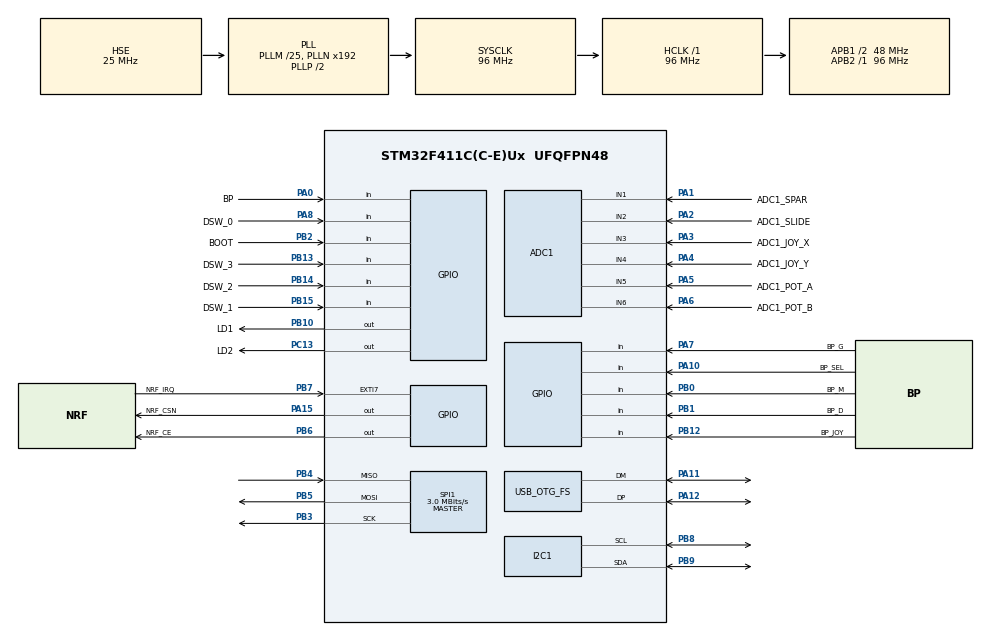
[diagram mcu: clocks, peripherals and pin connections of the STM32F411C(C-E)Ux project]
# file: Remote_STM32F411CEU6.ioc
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ADC1.Channel-0\#ChannelRegularConversion=ADC_CHANNEL_1
ADC1.Channel-1\#ChannelRegularConversion=ADC_CHANNEL_2
ADC1.Channel-2\#ChannelRegularConversion=ADC_CHANNEL_3
ADC1.Channel-3\#ChannelRegularConversion=ADC_CHANNEL_4
ADC1.Channel-4\#ChannelRegularConversion=ADC_CHANNEL_5
ADC1.Channel-5\#ChannelRegularConversion=ADC_CHANNEL_6
ADC1.ContinuousConvMode=ENABLE
ADC1.DMAContinuousRequests=ENABLE
ADC1.DataAlign=ADC_DATAALIGN_RIGHT
ADC1.NbrOfConversion=6
ADC1.NbrOfConversionFlag=1
ADC1.Rank-0\#ChannelRegularConversion=1
ADC1.Rank-1\#ChannelRegularConversion=2
ADC1.Rank-2\#ChannelRegularConversion=3
ADC1.Rank-3\#ChannelRegularConversion=4
ADC1.Rank-4\#ChannelRegularConversion=5
ADC1.Rank-5\#ChannelRegularConversion=6
ADC1.SamplingTime-0\#ChannelRegularConversion=ADC_SAMPLETIME_480CYCLES
ADC1.SamplingTime-1\#ChannelRegularConversion=ADC_SAMPLETIME_480CYCLES
ADC1.SamplingTime-2\#ChannelRegularConversion=ADC_SAMPLETIME_480CYCLES
ADC1.SamplingTime-3\#ChannelRegularConversion=ADC_SAMPLETIME_480CYCLES
ADC1.SamplingTime-4\#ChannelRegularConversion=ADC_SAMPLETIME_480CYCLES
ADC1.SamplingTime-5\#ChannelRegularConversion=ADC_SAMPLETIME_480CYCLES
ADC1.master=1
Dma.ADC1.0.Direction=DMA_PERIPH_TO_MEMORY
Dma.ADC1.0.FIFOMode=DMA_FIFOMODE_DISABLE
Dma.ADC1.0.Instance=DMA2_Stream0
Dma.ADC1.0.MemDataAlignment=DMA_MDATAALIGN_WORD
Dma.ADC1.0.MemInc=DMA_MINC_ENABLE
Dma.ADC1.0.Mode=DMA_CIRCULAR
Dma.ADC1.0.PeriphDataAlignment=DMA_PDATAALIGN_WORD
Dma.ADC1.0.PeriphInc=DMA_PINC_DISABLE
Dma.ADC1.0.Priority=DMA_PRIORITY_HIGH
Dma.Request0=ADC1
FREERTOS.Tasks01=defaultTask,24,128,StartDefaultTask,Default,NULL,Dynamic,NULL,NULL;send_usb_data,24,128,send_usb_data_func,Default,NULL,Dynamic,NULL,NULL;read_nrf,25,128,read_nrf_func,Default,NULL,Dynamic,NULL,NULL;send_nrf,26,128,send_nrf_func,Default,NULL,Dynamic,NULL,NULL
FREERTOS.configUSE_NEWLIB_REENTRANT=1
Mcu.Family=STM32F4
Mcu.Name=STM32F411C(C-E)Ux
Mcu.Package=UFQFPN48
NVIC.ADC_IRQn=true\:5\:0\:true\:false\:true\:true\:true\:true\:true
NVIC.DMA2_Stream0_IRQn=true\:5\:0\:false\:false\:true\:true\:false\:true\:true
NVIC.OTG_FS_IRQn=true\:5\:0\:false\:false\:true\:true\:false\:true\:true
NVIC.PriorityGroup=NVIC_PRIORITYGROUP_4
NVIC.TIM2_IRQn=true\:15\:0\:false\:false\:true\:false\:false\:true\:true
NVIC.TimeBase=TIM2_IRQn
NVIC.TimeBaseIP=TIM2
PA0-WKUP.GPIO_Label=BP
PA0-WKUP.GPIO_PuPd=GPIO_PULLUP
PA0-WKUP.Signal=GPIO_Input
PA1.GPIO_Label=ADC1_SPAR
PA1.Signal=ADCx_IN1
PA10.GPIO_Label=BP_SEL
PA10.GPIO_PuPd=GPIO_PULLUP
PA10.Signal=GPIO_Input
PA11.Mode=Device_Only
PA11.Signal=USB_OTG_FS_DM
PA12.Mode=Device_Only
PA12.Signal=USB_OTG_FS_DP
PA13.Mode=Serial_Wire
PA13.Signal=SYS_JTMS-SWDIO
PA14.Mode=Serial_Wire
PA14.Signal=SYS_JTCK-SWCLK
PA15.GPIO_Label=NRF_CSN
PA15.Signal=GPIO_Output
PA2.GPIO_Label=ADC1_SLIDE
PA2.Signal=ADCx_IN2
PA3.GPIO_Label=ADC1_JOY_X
PA3.Signal=ADCx_IN3
PA4.GPIO_Label=ADC1_JOY_Y
PA4.Signal=ADCx_IN4
PA5.GPIO_Label=ADC1_POT_A
PA5.Signal=ADCx_IN5
PA6.GPIO_Label=ADC1_POT_B
PA6.Signal=ADCx_IN6
PA7.GPIO_Label=BP_G
PA7.GPIO_PuPd=GPIO_PULLUP
PA7.Signal=GPIO_Input
PA8.GPIO_Label=DSW_0
PA8.GPIO_PuPd=GPIO_PULLUP
PA8.Signal=GPIO_Input
PB0.GPIO_Label=BP_M
PB0.GPIO_PuPd=GPIO_PULLUP
PB0.Signal=GPIO_Input
PB1.GPIO_Label=BP_D
PB1.GPIO_PuPd=GPIO_PULLUP
PB1.Signal=GPIO_Input
PB10.GPIO_Label=LD1
PB10.Signal=GPIO_Output
PB12.GPIO_Label=BP_JOY
PB12.GPIO_PuPd=GPIO_PULLUP
PB12.Signal=GPIO_Input
PB13.GPIO_Label=DSW_3
PB13.GPIO_PuPd=GPIO_PULLUP
PB13.Signal=GPIO_Input
PB14.GPIO_Label=DSW_2
PB14.GPIO_PuPd=GPIO_PULLUP
PB14.Signal=GPIO_Input
PB15.GPIO_Label=DSW_1
PB15.GPIO_PuPd=GPIO_PULLUP
PB15.Signal=GPIO_Input
PB2.GPIO_Label=BOOT
PB2.GPIO_PuPd=GPIO_NOPULL
PB2.Signal=GPIO_Input
PB3.Mode=Full_Duplex_Master
PB3.Signal=SPI1_SCK
PB4.Mode=Full_Duplex_Master
PB4.Signal=SPI1_MISO
PB5.Mode=Full_Duplex_Master
PB5.Signal=SPI1_MOSI
PB6.GPIO_Label=NRF_CE
PB6.Signal=GPIO_Output
PB7.GPIO_Label=NRF_IRQ
PB7.Signal=GPXTI7
PB8.Mode=I2C
PB8.Signal=I2C1_SCL
PB9.Mode=I2C
PB9.Signal=I2C1_SDA
PC13-ANTI_TAMP.GPIO_Label=LD2
PC13-ANTI_TAMP.GPIO_ModeDefaultOutputPP=GPIO_MODE_OUTPUT_OD
PC13-ANTI_TAMP.GPIO_PuPd=GPIO_NOPULL
PC13-ANTI_TAMP.Signal=GPIO_Output
PC14-OSC32_IN.Mode=LSE-External-Oscillator
PC14-OSC32_IN.Signal=RCC_OSC32_IN
PC15-OSC32_OUT.Mode=LSE-External-Oscillator
PC15-OSC32_OUT.Signal=RCC_OSC32_OUT
PH0\ -\ OSC_IN.Mode=HSE-External-Oscillator
PH0\ -\ OSC_IN.Signal=RCC_OSC_IN
PH1\ -\ OSC_OUT.Mode=HSE-External-Oscillator
PH1\ -\ OSC_OUT.Signal=RCC_OSC_OUT
ProjectManager.HeapSize=0x200
ProjectManager.StackSize=0x400
ProjectManager.TargetToolchain=STM32CubeIDE
RCC.48MHZClocksFreq_Value=48000000
RCC.AHBFreq_Value=96000000
RCC.APB1CLKDivider=RCC_HCLK_DIV2
RCC.APB1Freq_Value=48000000
RCC.APB1TimFreq_Value=96000000
RCC.APB2Freq_Value=96000000
RCC.APB2TimFreq_Value=96000000
RCC.CortexFreq_Value=96000000
RCC.HCLKFreq_Value=96000000
RCC.HSE_Timout=100
RCC.HSE_VALUE=25000000
RCC.HSI_VALUE=16000000
RCC.PLLM=25
RCC.SYSCLKFreq_VALUE=96000000
RCC.SYSCLKSource=RCC_SYSCLKSOURCE_PLLCLK
RCC.VCOOutputFreq_Value=192000000
SH.ADCx_IN1.0=ADC1_IN1,IN1
SH.ADCx_IN2.0=ADC1_IN2,IN2
SH.ADCx_IN3.0=ADC1_IN3,IN3
SH.ADCx_IN4.0=ADC1_IN4,IN4
SH.ADCx_IN5.0=ADC1_IN5,IN5
SH.ADCx_IN6.0=ADC1_IN6,IN6
SPI1.BaudRatePrescaler=SPI_BAUDRATEPRESCALER_32
SPI1.CalculateBaudRate=3.0 MBits/s
SPI1.Direction=SPI_DIRECTION_2LINES
SPI1.Mode=SPI_MODE_MASTER
SPI1.VirtualType=VM_MASTER
USB_DEVICE.CLASS_NAME_FS=CDC
USB_DEVICE.VirtualMode=Cdc
USB_DEVICE.VirtualModeFS=Cdc_FS
USB_OTG_FS.VirtualMode=Device_Only
VP_FREERTOS_VS_CMSIS_V2.Mode=CMSIS_V2
VP_SYS_VS_tim2.Mode=TIM2
VP_USB_DEVICE_VS_USB_DEVICE_CDC_FS.Mode=CDC_FS
board=custom

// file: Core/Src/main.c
/* USER CODE BEGIN Header */
/**
  ******************************************************************************
  * @file           : main.c
  * @brief          : Main program body
  ******************************************************************************
  * @attention
  *
  * Copyright (c) 2025 STMicroelectronics.
  * All rights reserved.
  *
  * This software is licensed under terms that can be found in the LICENSE file
  * in the root directory of this software component.
  * If no LICENSE file comes with this software, it is provided AS-IS.
  *
  ******************************************************************************
  */
/* USER CODE END Header */
#include "main.h"
#include "cmsis_os.h"
#include "usb_device.h"

/* USER CODE BEGIN Includes */
#include "usbd_cdc_if.h"
#include "radio.h"
/* USER CODE END Includes */

ADC_HandleTypeDef hadc1;
DMA_HandleTypeDef hdma_adc1;

I2C_HandleTypeDef hi2c1;

SPI_HandleTypeDef hspi1;

/* Definitions for defaultTask */
osThreadId_t defaultTaskHandle;
const osThreadAttr_t defaultTask_attributes = {
  .name = "defaultTask",
  .stack_size = 128 * 4,
  .priority = (osPriority_t) osPriorityNormal,
};
/* Definitions for send_usb_data */
osThreadId_t send_usb_dataHandle;
const osThreadAttr_t send_usb_data_attributes = {
  .name = "send_usb_data",
  .stack_size = 128 * 4,
  .priority = (osPriority_t) osPriorityNormal,
};
/* Definitions for read_nrf */
osThreadId_t read_nrfHandle;
const osThreadAttr_t read_nrf_attributes = {
  .name = "read_nrf",
  .stack_size = 128 * 4,
  .priority = (osPriority_t) osPriorityNormal1,
};
/* Definitions for send_nrf */
osThreadId_t send_nrfHandle;
const osThreadAttr_t send_nrf_attributes = {
  .name = "send_nrf",
  .stack_size = 128 * 4,
  .priority = (osPriority_t) osPriorityNormal2,
};
/* USER CODE BEGIN PV */
uint16_t pot1;
uint16_t pot2;
uint16_t pot3;
uint16_t pot4;
uint16_t pot5;
uint16_t pot6;
uint32_t readvalue[6];
/* USER CODE END PV */

void SystemClock_Config(void);
static void MX_GPIO_Init(void);
static void MX_DMA_Init(void);
static void MX_SPI1_Init(void);
static void MX_I2C1_Init(void);
static void MX_ADC1_Init(void);
void StartDefaultTask(void *argument);
void send_usb_data_func(void *argument);
void read_nrf_func(void *argument);
void send_nrf_func(void *argument);

int main(void)
{

  /* MCU Configuration--------------------------------------------------------*/

  /* Reset of all peripherals, Initializes the Flash interface and the Systick. */
  HAL_Init();

  /* Configure the system clock */
  SystemClock_Config();

  /* Initialize all configured peripherals */
  MX_GPIO_Init();
  MX_DMA_Init();
  MX_SPI1_Init();
  MX_I2C1_Init();
  MX_ADC1_Init();

  /* Init scheduler */
  osKernelInitialize();

  /* Create the thread(s) */
  /* creation of defaultTask */
  defaultTaskHandle = osThreadNew(StartDefaultTask, NULL, &defaultTask_attributes);

  /* creation of send_usb_data */
  send_usb_dataHandle = osThreadNew(send_usb_data_func, NULL, &send_usb_data_attributes);

  /* creation of read_nrf */
  read_nrfHandle = osThreadNew(read_nrf_func, NULL, &read_nrf_attributes);

  /* creation of send_nrf */
  send_nrfHandle = osThreadNew(send_nrf_func, NULL, &send_nrf_attributes);

  /* Start scheduler */
  osKernelStart();

  /* We should never get here as control is now taken by the scheduler */

  /* Infinite loop */
  while (1)
  {

  }
}

void SystemClock_Config(void)
{
  RCC_OscInitTypeDef RCC_OscInitStruct = {0};
  RCC_ClkInitTypeDef RCC_ClkInitStruct = {0};

  /** Configure the main internal regulator output voltage
  */
  __HAL_RCC_PWR_CLK_ENABLE();
  __HAL_PWR_VOLTAGESCALING_CONFIG(PWR_REGULATOR_VOLTAGE_SCALE1);

  /** Initializes the RCC Oscillators according to the specified parameters
  * in the RCC_OscInitTypeDef structure.
  */
  RCC_OscInitStruct.OscillatorType = RCC_OSCILLATORTYPE_HSE;
  RCC_OscInitStruct.HSEState = RCC_HSE_ON;
  RCC_OscInitStruct.PLL.PLLState = RCC_PLL_ON;
  RCC_OscInitStruct.PLL.PLLSource = RCC_PLLSOURCE_HSE;
  RCC_OscInitStruct.PLL.PLLM = 25;
  RCC_OscInitStruct.PLL.PLLN = 192;
  RCC_OscInitStruct.PLL.PLLP = RCC_PLLP_DIV2;
  RCC_OscInitStruct.PLL.PLLQ = 4;
  if (HAL_RCC_OscConfig(&RCC_OscInitStruct) != HAL_OK)
  {
    Error_Handler();
  }

  /** Initializes the CPU, AHB and APB buses clocks
  */
  RCC_ClkInitStruct.ClockType = RCC_CLOCKTYPE_HCLK|RCC_CLOCKTYPE_SYSCLK
                              |RCC_CLOCKTYPE_PCLK1|RCC_CLOCKTYPE_PCLK2;
  RCC_ClkInitStruct.SYSCLKSource = RCC_SYSCLKSOURCE_PLLCLK;
  RCC_ClkInitStruct.AHBCLKDivider = RCC_SYSCLK_DIV1;
  RCC_ClkInitStruct.APB1CLKDivider = RCC_HCLK_DIV2;
  RCC_ClkInitStruct.APB2CLKDivider = RCC_HCLK_DIV1;

  if (HAL_RCC_ClockConfig(&RCC_ClkInitStruct, FLASH_LATENCY_3) != HAL_OK)
  {
    Error_Handler();
  }
}

static void MX_ADC1_Init(void)
{

  ADC_ChannelConfTypeDef sConfig = {0};

  /** Configure the global features of the ADC (Clock, Resolution, Data Alignment and number of conversion)
  */
  hadc1.Instance = ADC1;
  hadc1.Init.ClockPrescaler = ADC_CLOCK_SYNC_PCLK_DIV4;
  hadc1.Init.Resolution = ADC_RESOLUTION_12B;
  hadc1.Init.ScanConvMode = ENABLE;
  hadc1.Init.ContinuousConvMode = ENABLE;
  hadc1.Init.DiscontinuousConvMode = DISABLE;
  hadc1.Init.ExternalTrigConvEdge = ADC_EXTERNALTRIGCONVEDGE_NONE;
  hadc1.Init.ExternalTrigConv = ADC_SOFTWARE_START;
  hadc1.Init.DataAlign = ADC_DATAALIGN_RIGHT;
  hadc1.Init.NbrOfConversion = 6;
  hadc1.Init.DMAContinuousRequests = ENABLE;
  hadc1.Init.EOCSelection = ADC_EOC_SINGLE_CONV;
  if (HAL_ADC_Init(&hadc1) != HAL_OK)
  {
    Error_Handler();
  }

  /** Configure for the selected ADC regular channel its corresponding rank in the sequencer and its sample time.
  */
  sConfig.Channel = ADC_CHANNEL_1;
  sConfig.Rank = 1;
  sConfig.SamplingTime = ADC_SAMPLETIME_480CYCLES;
  if (HAL_ADC_ConfigChannel(&hadc1, &sConfig) != HAL_OK)
  {
    Error_Handler();
  }

  /** Configure for the selected ADC regular channel its corresponding rank in the sequencer and its sample time.
  */
  sConfig.Channel = ADC_CHANNEL_2;
  sConfig.Rank = 2;
  if (HAL_ADC_ConfigChannel(&hadc1, &sConfig) != HAL_OK)
  {
    Error_Handler();
  }

  /** Configure for the selected ADC regular channel its corresponding rank in the sequencer and its sample time.
  */
  sConfig.Channel = ADC_CHANNEL_3;
  sConfig.Rank = 3;
  if (HAL_ADC_ConfigChannel(&hadc1, &sConfig) != HAL_OK)
  {
    Error_Handler();
  }

  /** Configure for the selected ADC regular channel its corresponding rank in the sequencer and its sample time.
  */
  sConfig.Channel = ADC_CHANNEL_4;
  sConfig.Rank = 4;
  if (HAL_ADC_ConfigChannel(&hadc1, &sConfig) != HAL_OK)
  {
    Error_Handler();
  }

  /** Configure for the selected ADC regular channel its corresponding rank in the sequencer and its sample time.
  */
  sConfig.Channel = ADC_CHANNEL_5;
  sConfig.Rank = 5;
  if (HAL_ADC_ConfigChannel(&hadc1, &sConfig) != HAL_OK)
  {
    Error_Handler();
  }

  /** Configure for the selected ADC regular channel its corresponding rank in the sequencer and its sample time.
  */
  sConfig.Channel = ADC_CHANNEL_6;
  sConfig.Rank = 6;
  if (HAL_ADC_ConfigChannel(&hadc1, &sConfig) != HAL_OK)
  {
    Error_Handler();
  }

}

static void MX_I2C1_Init(void)
{

  hi2c1.Instance = I2C1;
  hi2c1.Init.ClockSpeed = 100000;
  hi2c1.Init.DutyCycle = I2C_DUTYCYCLE_2;
  hi2c1.Init.OwnAddress1 = 0;
  hi2c1.Init.AddressingMode = I2C_ADDRESSINGMODE_7BIT;
  hi2c1.Init.DualAddressMode = I2C_DUALADDRESS_DISABLE;
  hi2c1.Init.OwnAddress2 = 0;
  hi2c1.Init.GeneralCallMode = I2C_GENERALCALL_DISABLE;
  hi2c1.Init.NoStretchMode = I2C_NOSTRETCH_DISABLE;
  if (HAL_I2C_Init(&hi2c1) != HAL_OK)
  {
    Error_Handler();
  }

}

static void MX_SPI1_Init(void)
{

  /* SPI1 parameter configuration*/
  hspi1.Instance = SPI1;
  hspi1.Init.Mode = SPI_MODE_MASTER;
  hspi1.Init.Direction = SPI_DIRECTION_2LINES;
  hspi1.Init.DataSize = SPI_DATASIZE_8BIT;
  hspi1.Init.CLKPolarity = SPI_POLARITY_LOW;
  hspi1.Init.CLKPhase = SPI_PHASE_1EDGE;
  hspi1.Init.NSS = SPI_NSS_SOFT;
  hspi1.Init.BaudRatePrescaler = SPI_BAUDRATEPRESCALER_32;
  hspi1.Init.FirstBit = SPI_FIRSTBIT_MSB;
  hspi1.Init.TIMode = SPI_TIMODE_DISABLE;
  hspi1.Init.CRCCalculation = SPI_CRCCALCULATION_DISABLE;
  hspi1.Init.CRCPolynomial = 10;
  if (HAL_SPI_Init(&hspi1) != HAL_OK)
  {
    Error_Handler();
  }

}

static void MX_DMA_Init(void)
{

  /* DMA controller clock enable */
  __HAL_RCC_DMA2_CLK_ENABLE();

  /* DMA interrupt init */
  /* DMA2_Stream0_IRQn interrupt configuration */
  HAL_NVIC_SetPriority(DMA2_Stream0_IRQn, 5, 0);
  HAL_NVIC_EnableIRQ(DMA2_Stream0_IRQn);

}

static void MX_GPIO_Init(void)
{
  GPIO_InitTypeDef GPIO_InitStruct = {0};

  /* GPIO Ports Clock Enable */
  __HAL_RCC_GPIOC_CLK_ENABLE();
  __HAL_RCC_GPIOH_CLK_ENABLE();
  __HAL_RCC_GPIOA_CLK_ENABLE();
  __HAL_RCC_GPIOB_CLK_ENABLE();

  /*Configure GPIO pin Output Level */
  HAL_GPIO_WritePin(LD2_GPIO_Port, LD2_Pin, GPIO_PIN_RESET);

  /*Configure GPIO pin Output Level */
  HAL_GPIO_WritePin(GPIOB, LD1_Pin|NRF_CE_Pin, GPIO_PIN_RESET);

  /*Configure GPIO pin Output Level */
  HAL_GPIO_WritePin(NRF_CSN_GPIO_Port, NRF_CSN_Pin, GPIO_PIN_RESET);

  /*Configure GPIO pin : LD2_Pin */
  GPIO_InitStruct.Pin = LD2_Pin;
  GPIO_InitStruct.Mode = GPIO_MODE_OUTPUT_OD;
  GPIO_InitStruct.Pull = GPIO_NOPULL;
  GPIO_InitStruct.Speed = GPIO_SPEED_FREQ_LOW;
  HAL_GPIO_Init(LD2_GPIO_Port, &GPIO_InitStruct);

  /*Configure GPIO pins : BP_Pin BP_G_Pin DSW_0_Pin BP_SEL_Pin */
  GPIO_InitStruct.Pin = BP_Pin|BP_G_Pin|DSW_0_Pin|BP_SEL_Pin;
  GPIO_InitStruct.Mode = GPIO_MODE_INPUT;
  GPIO_InitStruct.Pull = GPIO_PULLUP;
  HAL_GPIO_Init(GPIOA, &GPIO_InitStruct);

  /*Configure GPIO pins : BP_M_Pin BP_D_Pin BP_JOY_Pin DSW_3_Pin
                           DSW_2_Pin DSW_1_Pin */
  GPIO_InitStruct.Pin = BP_M_Pin|BP_D_Pin|BP_JOY_Pin|DSW_3_Pin
                          |DSW_2_Pin|DSW_1_Pin;
  GPIO_InitStruct.Mode = GPIO_MODE_INPUT;
  GPIO_InitStruct.Pull = GPIO_PULLUP;
  HAL_GPIO_Init(GPIOB, &GPIO_InitStruct);

  /*Configure GPIO pin : BOOT_Pin */
  GPIO_InitStruct.Pin = BOOT_Pin;
  GPIO_InitStruct.Mode = GPIO_MODE_INPUT;
  GPIO_InitStruct.Pull = GPIO_NOPULL;
  HAL_GPIO_Init(BOOT_GPIO_Port, &GPIO_InitStruct);

  /*Configure GPIO pins : LD1_Pin NRF_CE_Pin */
  GPIO_InitStruct.Pin = LD1_Pin|NRF_CE_Pin;
  GPIO_InitStruct.Mode = GPIO_MODE_OUTPUT_PP;
  GPIO_InitStruct.Pull = GPIO_NOPULL;
  GPIO_InitStruct.Speed = GPIO_SPEED_FREQ_LOW;
  HAL_GPIO_Init(GPIOB, &GPIO_InitStruct);

  /*Configure GPIO pin : NRF_CSN_Pin */
  GPIO_InitStruct.Pin = NRF_CSN_Pin;
  GPIO_InitStruct.Mode = GPIO_MODE_OUTPUT_PP;
  GPIO_InitStruct.Pull = GPIO_NOPULL;
  GPIO_InitStruct.Speed = GPIO_SPEED_FREQ_LOW;
  HAL_GPIO_Init(NRF_CSN_GPIO_Port, &GPIO_InitStruct);

  /*Configure GPIO pin : NRF_IRQ_Pin */
  GPIO_InitStruct.Pin = NRF_IRQ_Pin;
  GPIO_InitStruct.Mode = GPIO_MODE_IT_RISING;
  GPIO_InitStruct.Pull = GPIO_NOPULL;
  HAL_GPIO_Init(NRF_IRQ_GPIO_Port, &GPIO_InitStruct);

}

void StartDefaultTask(void *argument)
{
  /* init code for USB_DEVICE */
  MX_USB_DEVICE_Init();
  /* USER CODE BEGIN 5 */
  HAL_ADC_Start_DMA(&hadc1, (uint32_t*)readvalue, 6);
  runRadio();
  /* Infinite loop */
  for(;;)
  {
    osDelay(1);
  }
  /* USER CODE END 5 */
}

void send_usb_data_func(void *argument)
{
  for(;;)
  {
    osDelay(1);
  }
}

void read_nrf_func(void *argument)
{
  for(;;)
  {
    osDelay(1);
  }
}

void send_nrf_func(void *argument)
{
  for(;;)
  {
    osDelay(1);
  }
}

void HAL_TIM_PeriodElapsedCallback(TIM_HandleTypeDef *htim)
{
  if (htim->Instance == TIM2)
  {
    HAL_IncTick();
  }
}

void Error_Handler(void)
{
  __disable_irq();
  while (1)
  {
  }
}
